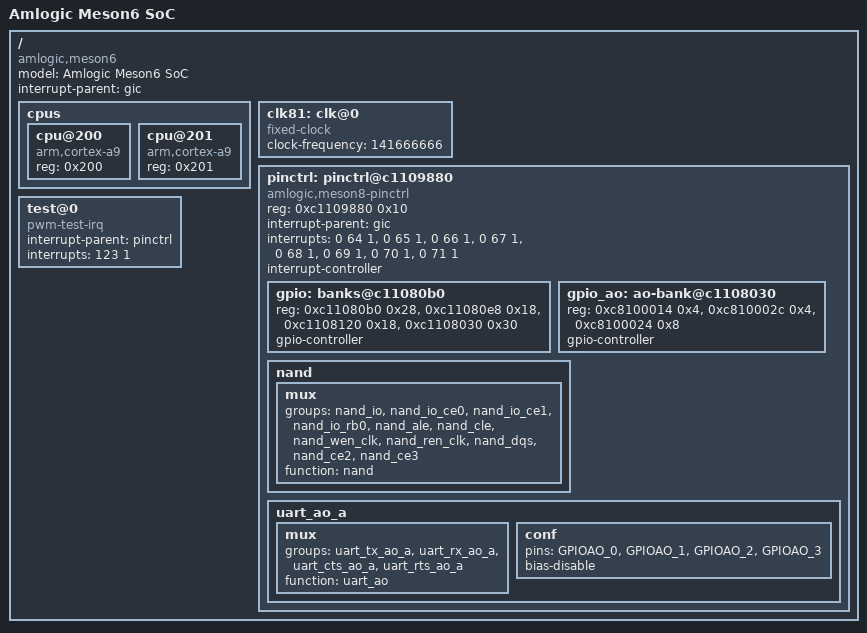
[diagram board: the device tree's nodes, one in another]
/*
 * Copyright 2014 Carlo Caione <carlo@caione.org>
 *
 * This file is dual-licensed: you can use it either under the terms
 * of the GPL or the X11 license, at your option. Note that this dual
 * licensing only applies to this file, and not this project as a
 * whole.
 *
 *  a) This library is free software; you can redistribute it and/or
 *     modify it under the terms of the GNU General Public License as
 *     published by the Free Software Foundation; either version 2 of the
 *     License, or (at your option) any later version.
 *
 *     This library is distributed in the hope that it will be useful,
 *     but WITHOUT ANY WARRANTY; without even the implied warranty of
 *     MERCHANTABILITY or FITNESS FOR A PARTICULAR PURPOSE.  See the
 *     GNU General Public License for more details.
 *
 *     You should have received a copy of the GNU General Public
 *     License along with this library; if not, write to the Free
 *     Software Foundation, Inc., 51 Franklin St, Fifth Floor, Boston,
 *     MA 02110-1301 USA
 *
 * Or, alternatively,
 *
 *  b) Permission is hereby granted, free of charge, to any person
 *     obtaining a copy of this software and associated documentation
 *     files (the "Software"), to deal in the Software without
 *     restriction, including without limitation the rights to use,
 *     copy, modify, merge, publish, distribute, sublicense, and/or
 *     sell copies of the Software, and to permit persons to whom the
 *     Software is furnished to do so, subject to the following
 *     conditions:
 *
 *     The above copyright notice and this permission notice shall be
 *     included in all copies or substantial portions of the Software.
 *
 *     THE SOFTWARE IS PROVIDED "AS IS", WITHOUT WARRANTY OF ANY KIND,
 *     EXPRESS OR IMPLIED, INCLUDING BUT NOT LIMITED TO THE WARRANTIES
 *     OF MERCHANTABILITY, FITNESS FOR A PARTICULAR PURPOSE AND
 *     NONINFRINGEMENT. IN NO EVENT SHALL THE AUTHORS OR COPYRIGHT
 *     HOLDERS BE LIABLE FOR ANY CLAIM, DAMAGES OR OTHER LIABILITY,
 *     WHETHER IN AN ACTION OF CONTRACT, TORT OR OTHERWISE, ARISING
 *     FROM, OUT OF OR IN CONNECTION WITH THE SOFTWARE OR THE USE OR
 *     OTHER DEALINGS IN THE SOFTWARE.
 */

/include/ "meson.dtsi"

/ {
	model = "Amlogic Meson6 SoC";
	compatible = "amlogic,meson6";

	interrupt-parent = <&gic>;

	cpus {
		#address-cells = <1>;
		#size-cells = <0>;

		cpu@200 {
			device_type = "cpu";
			compatible = "arm,cortex-a9";
			reg = <0x200>;
		};

		cpu@201 {
			device_type = "cpu";
			compatible = "arm,cortex-a9";
			reg = <0x201>;
		};
	};

	clk81: clk@0 {
		#clock-cells = <0>;
		compatible = "fixed-clock";
		clock-frequency = <141666666>;
	};

	pinctrl: pinctrl@c1109880 {
		compatible = "amlogic,meson8-pinctrl";
		reg = <0xc1109880 0x10>;
		reg-names = "irq";
		interrupt-parent = <&gic>;
                interrupts = <0 64 1>, <0 65 1>, <0 66 1>, <0 67 1>,
			     <0 68 1>, <0 69 1>, <0 70 1>, <0 71 1>;
		interrupt-controller;
		#interrupt-cells = <2>;
		#address-cells = <1>;
		#size-cells = <1>;
		ranges;

		gpio: banks@c11080b0 {
			reg = <0xc11080b0 0x28>,
			      <0xc11080e8 0x18>,
			      <0xc1108120 0x18>,
			      <0xc1108030 0x30>;
			reg-names = "mux", "pull", "pull-enable", "gpio";
			gpio-controller;
			#gpio-cells = <2>;
               };

		gpio_ao: ao-bank@c1108030 {
			reg = <0xc8100014 0x4>,
			      <0xc810002c 0x4>,
			      <0xc8100024 0x8>;
			reg-names = "mux", "pull", "gpio";
			gpio-controller;
			#gpio-cells = <2>;
		};

		nand {
			mux {
				groups = "nand_io", "nand_io_ce0", "nand_io_ce1",
					 "nand_io_rb0", "nand_ale", "nand_cle",
					 "nand_wen_clk", "nand_ren_clk", "nand_dqs",
					 "nand_ce2", "nand_ce3";
				function = "nand";
			};
		};

		uart_ao_a {
			mux {
				groups = "uart_tx_ao_a", "uart_rx_ao_a",
					 "uart_cts_ao_a", "uart_rts_ao_a";
				function = "uart_ao";
			};

			conf {
				pins = "GPIOAO_0", "GPIOAO_1",
				       "GPIOAO_2", "GPIOAO_3";
				bias-disable;
			};
		};
	};


        test@0 {
                compatible = "pwm-test-irq";
                interrupt-parent = <&pinctrl>;
                interrupts = <123 1>;
        };

}; /* end of / */
